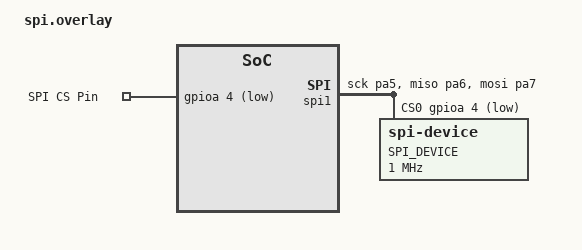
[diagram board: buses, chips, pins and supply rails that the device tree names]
/ {
    aliases {
        myspi = &spi1;
        mycs = &mycs_gpio;
    };

    gpio_cs {
        compatible = "gpio-keys";
        mycs_gpio: mycs {
            gpios = <&gpioa 4 GPIO_ACTIVE_LOW>;
            label = "SPI CS Pin";
        };
    };
};

&spi1 {
    status = "okay";
    pinctrl-0 = <&spi1_sck_pa5 &spi1_miso_pa6 &spi1_mosi_pa7>;
    pinctrl-names = "default";
    cs-gpios = <&gpioa 4 GPIO_ACTIVE_LOW>;

    spi_device: spi-device@0 {
        compatible = "zephyr,spi-device";
        reg = <0>;
        spi-max-frequency = <1000000>; /* 1 MHz */
        label = "SPI_DEVICE";
    };
};
